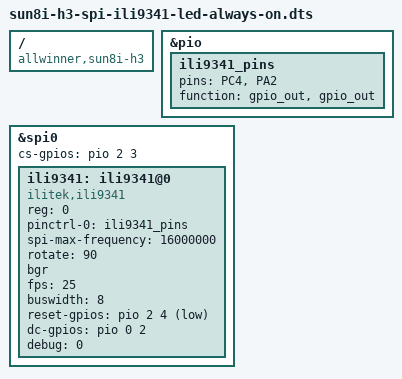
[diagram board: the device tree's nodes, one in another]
/dts-v1/;
/plugin/;

/ {
  compatible = "allwinner,sun8i-h3";

  fragment@0 {
    target = <&pio>;
    __overlay__ {
      ili9341_pins: ili9341_pins {
        pins = "PC4", "PA2"; /*RESET, DC_RS*/
        function = "gpio_out", "gpio_out" ;
      };
    };
  };

  fragment@1 {
    target = <&spi0>;
    __overlay__ {
      status = "okay";
      cs-gpios = <&pio 2 3 0>; /* PC3 */

      ili9341: ili9341@0 {
        compatible = "ilitek,ili9341";
        reg = <0>;
        pinctrl-names = "default";
        pinctrl-0 = <&ili9341_pins>;
        spi-max-frequency = <16000000>;
        rotate = <90>;
        bgr;
        fps = <25>;
        buswidth = <8>;
        reset-gpios = <&pio 2 4 1>; /*RESET=PC4*/
        dc-gpios = <&pio 0 2 0>; /*DC_RS=PA2*/
        /*led-gpios = <&pio 2 4 0>; LED=PC4*/
        debug = <0>;
      };
    };
  };
};
